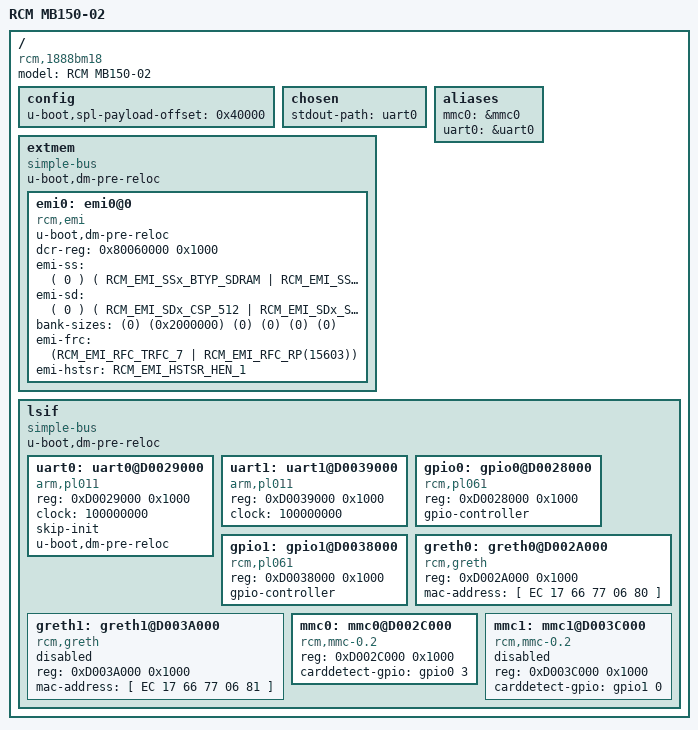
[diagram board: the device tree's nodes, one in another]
#include <dt-bindings/memory/rcm-emi.h>

/dts-v1/;
/
{
	compatible = "rcm,1888bm18";
	model = "RCM MB150-02";
	#address-cells = <1>;
	#size-cells = <1>;

	config {
		u-boot,spl-payload-offset = <0x40000>;
	};

	chosen {
		stdout-path = "uart0";
	};

	aliases {
		mmc0 = &mmc0;
		uart0 = &uart0;
	};

	extmem {
		u-boot,dm-pre-reloc;
		compatible = "simple-bus";
		#address-cells = <1>;
		#size-cells = <1>;

		emi0: emi0@0 {
			u-boot,dm-pre-reloc;
			compatible = "rcm,emi";
			dcr-reg = <0x80060000 0x1000>;
			emi-ss = <
				(	/* BANK 0 */
					0
				)
				(	/* BANK 1 */
					RCM_EMI_SSx_BTYP_SDRAM |
					RCM_EMI_SSx_PTYP_NO_PAGES |
					RCM_EMI_SSx_SRDY_EXT_RDY_NOT_USE |
					RCM_EMI_SSx_TWR_0 |
					RCM_EMI_SSx_SST_FLOW_THROUGH |
					RCM_EMI_SSx_TSSOE_1 |
					RCM_EMI_SSx_TSOE_1 |
					RCM_EMI_SSx_TCYC_8 |
					RCM_EMI_SSx_RDY(0) |
					RCM_EMI_SSx_TDEL_0
				) 
				(	/* BANK 2 */
					0
				)
				(	/* BANK 3 */
					0
				)
				(	/* BANK 4 */
					0
				)
				(	/* BANK 5 */
					0
				)
			>;
			emi-sd = <
				(	/* BANK 0 */
					0
				)
				(	/* BANK 1 */
					RCM_EMI_SDx_CSP_512 |
					RCM_EMI_SDx_SDS_8M |
					RCM_EMI_SDx_CL_3 |
					RCM_EMI_SDx_TRDL_2 |
					RCM_EMI_SDx_SI_CPU_INIT |
					RCM_EMI_SDx_T_RCD_3 |
					RCM_EMI_SDx_T_RAS_5
				)
				(	/* BANK 2 */
					0
				)
				(	/* BANK 3 */
					0
				)
				(	/* BANK 4 */
					0
				)
				(	/* BANK 5 */
					0
				)
			>;
			bank-sizes = <
				(0) /* BANK 0 */
				(0x2000000) /* BANK 1 - 32MB */
				(0) /* BANK 2 */
				(0) /* BANK 3 */
				(0) /* BANK 4 */
				(0) /* BANK 5 */
			>;
			emi-frc = <(RCM_EMI_RFC_TRFC_7 | RCM_EMI_RFC_RP(15603))>;
			emi-hstsr = <RCM_EMI_HSTSR_HEN_1>;
		};
	};

	lsif {
		u-boot,dm-pre-reloc;
		compatible = "simple-bus";
		#address-cells = <1>;
		#size-cells = <1>;

		// console
		uart0: uart0@D0029000 {
			compatible = "arm,pl011", "arm,primecell";
			reg = <0xD0029000 0x1000>;
			clock = <100000000>;
			skip-init; // the UART speed is configured by RUMBOOT and it depens on the board switches
			u-boot,dm-pre-reloc;
		};

		uart1: uart1@D0039000 {
			compatible = "arm,pl011", "arm,primecell";
			reg = <0xD0039000 0x1000>;
			clock = <100000000>;
		};

		gpio0: gpio0@D0028000 {
			compatible = "rcm,pl061";
			#address-cells = <1>;
			#size-cells = <0>;
			#gpio-cells = <2>;
			reg = <0xD0028000 0x1000>;
			gpio-controller;
		};

		gpio1: gpio1@D0038000 {
			compatible = "rcm,pl061";
			#address-cells = <1>;
			#size-cells = <0>;
			#gpio-cells = <2>;
			reg = <0xD0038000 0x1000>;
			gpio-controller;
		};

		greth0: greth0@D002A000 {
			compatible = "rcm,greth";
			reg = <0xD002A000 0x1000>;
			mac-address = [ EC 17 66 77 06 80 ];
		};

		greth1: greth1@D003A000 {
			compatible = "rcm,greth";
			reg = <0xD003A000 0x1000>;
			mac-address = [ EC 17 66 77 06 81 ];
			status = "disabled";
		};

		mmc0: mmc0@D002C000 {
			compatible = "rcm,mmc-0.2";
			reg = <0xD002C000 0x1000>;
			carddetect-gpio = <&gpio0 3 0>;
		};

		mmc1: mmc1@D003C000 {
			compatible = "rcm,mmc-0.2";
			reg = <0xD003C000 0x1000>;
			carddetect-gpio = <&gpio1 0 0>;
			status = "disabled";
		};
	};
};
